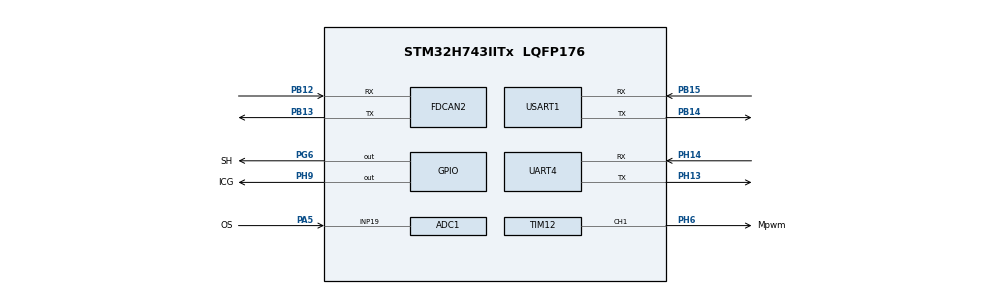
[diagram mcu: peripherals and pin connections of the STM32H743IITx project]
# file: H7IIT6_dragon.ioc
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ADC1.Channel-15\#ChannelRegularConversion=ADC_CHANNEL_19
ADC1.ClockPrescaler=ADC_CLOCK_ASYNC_DIV4
ADC1.ContinuousConvMode=ENABLE
ADC1.ConversionDataManagement=ADC_CONVERSIONDATA_DMA_CIRCULAR
ADC1.NbrOfConversionFlag=1
ADC1.OffsetNumber-15\#ChannelRegularConversion=ADC_OFFSET_NONE
ADC1.OffsetSignedSaturation-15\#ChannelRegularConversion=DISABLE
ADC1.Rank-15\#ChannelRegularConversion=1
ADC1.Resolution=ADC_RESOLUTION_12B
ADC1.SamplingTime-15\#ChannelRegularConversion=ADC_SAMPLETIME_1CYCLE_5
ADC1.master=1
CORTEX_M7.default_mode_Activation=1
Dma.ADC1.0.Direction=DMA_PERIPH_TO_MEMORY
Dma.ADC1.0.EventEnable=DISABLE
Dma.ADC1.0.FIFOMode=DMA_FIFOMODE_DISABLE
Dma.ADC1.0.Instance=DMA1_Stream0
Dma.ADC1.0.MemDataAlignment=DMA_MDATAALIGN_HALFWORD
Dma.ADC1.0.MemInc=DMA_MINC_ENABLE
Dma.ADC1.0.Mode=DMA_CIRCULAR
Dma.ADC1.0.PeriphDataAlignment=DMA_PDATAALIGN_HALFWORD
Dma.ADC1.0.PeriphInc=DMA_PINC_DISABLE
Dma.ADC1.0.Polarity=HAL_DMAMUX_REQ_GEN_RISING
Dma.ADC1.0.Priority=DMA_PRIORITY_LOW
Dma.ADC1.0.RequestNumber=1
Dma.ADC1.0.SignalID=NONE
Dma.ADC1.0.SyncEnable=DISABLE
Dma.ADC1.0.SyncPolarity=HAL_DMAMUX_SYNC_NO_EVENT
Dma.ADC1.0.SyncRequestNumber=1
Dma.ADC1.0.SyncSignalID=NONE
Dma.Request0=ADC1
Dma.Request1=UART4_TX
Dma.Request2=UART4_RX
Dma.UART4_RX.2.Direction=DMA_PERIPH_TO_MEMORY
Dma.UART4_RX.2.EventEnable=DISABLE
Dma.UART4_RX.2.FIFOMode=DMA_FIFOMODE_DISABLE
Dma.UART4_RX.2.Instance=DMA1_Stream2
Dma.UART4_RX.2.MemDataAlignment=DMA_MDATAALIGN_BYTE
Dma.UART4_RX.2.MemInc=DMA_MINC_ENABLE
Dma.UART4_RX.2.Mode=DMA_NORMAL
Dma.UART4_RX.2.PeriphDataAlignment=DMA_PDATAALIGN_BYTE
Dma.UART4_RX.2.PeriphInc=DMA_PINC_DISABLE
Dma.UART4_RX.2.Polarity=HAL_DMAMUX_REQ_GEN_RISING
Dma.UART4_RX.2.Priority=DMA_PRIORITY_LOW
Dma.UART4_RX.2.RequestNumber=1
Dma.UART4_RX.2.SignalID=NONE
Dma.UART4_RX.2.SyncEnable=DISABLE
Dma.UART4_RX.2.SyncPolarity=HAL_DMAMUX_SYNC_NO_EVENT
Dma.UART4_RX.2.SyncRequestNumber=1
Dma.UART4_RX.2.SyncSignalID=NONE
Dma.UART4_TX.1.Direction=DMA_MEMORY_TO_PERIPH
Dma.UART4_TX.1.EventEnable=DISABLE
Dma.UART4_TX.1.FIFOMode=DMA_FIFOMODE_DISABLE
Dma.UART4_TX.1.Instance=DMA1_Stream1
Dma.UART4_TX.1.MemDataAlignment=DMA_MDATAALIGN_BYTE
Dma.UART4_TX.1.MemInc=DMA_MINC_ENABLE
Dma.UART4_TX.1.Mode=DMA_NORMAL
Dma.UART4_TX.1.PeriphDataAlignment=DMA_PDATAALIGN_BYTE
Dma.UART4_TX.1.PeriphInc=DMA_PINC_DISABLE
Dma.UART4_TX.1.Polarity=HAL_DMAMUX_REQ_GEN_RISING
Dma.UART4_TX.1.Priority=DMA_PRIORITY_LOW
Dma.UART4_TX.1.RequestNumber=1
Dma.UART4_TX.1.SignalID=NONE
Dma.UART4_TX.1.SyncEnable=DISABLE
Dma.UART4_TX.1.SyncPolarity=HAL_DMAMUX_SYNC_NO_EVENT
Dma.UART4_TX.1.SyncRequestNumber=1
Dma.UART4_TX.1.SyncSignalID=NONE
FDCAN2.CalculateBaudRateNominal=1499999
FDCAN2.CalculateTimeBitNominal=666
FDCAN2.CalculateTimeQuantumNominal=133.33333333333334
Mcu.Family=STM32H7
Mcu.Name=STM32H743IITx
Mcu.Package=LQFP176
NVIC.DMA1_Stream0_IRQn=true\:0\:0\:false\:false\:true\:false\:true\:true
NVIC.DMA1_Stream1_IRQn=true\:0\:0\:false\:false\:true\:false\:true\:true
NVIC.DMA1_Stream2_IRQn=true\:0\:0\:false\:false\:true\:false\:true\:true
NVIC.PriorityGroup=NVIC_PRIORITYGROUP_4
NVIC.TIM2_IRQn=true\:0\:0\:false\:false\:true\:true\:true\:true
NVIC.UART4_IRQn=true\:0\:0\:false\:false\:true\:true\:true\:true
PA13\ (JTMS/SWDIO).Mode=Serial_Wire
PA13\ (JTMS/SWDIO).Signal=DEBUG_JTMS-SWDIO
PA14\ (JTCK/SWCLK).Mode=Serial_Wire
PA14\ (JTCK/SWCLK).Signal=DEBUG_JTCK-SWCLK
PA5.GPIO_Label=OS
PA5.Signal=ADCx_INP19
PB12.Mode=FDCAN_Activate
PB12.Signal=FDCAN2_RX
PB13.Mode=FDCAN_Activate
PB13.Signal=FDCAN2_TX
PB14.Mode=Asynchronous
PB14.Signal=USART1_TX
PB15.Mode=Asynchronous
PB15.Signal=USART1_RX
PG6.GPIO_Label=SH
PG6.Signal=GPIO_Output
PH13.GPIO_Speed=GPIO_SPEED_FREQ_VERY_HIGH
PH13.Mode=Asynchronous
PH13.Signal=UART4_TX
PH14.GPIO_Speed=GPIO_SPEED_FREQ_VERY_HIGH
PH14.Mode=Asynchronous
PH14.Signal=UART4_RX
PH6.GPIO_Label=Mpwm
PH6.Signal=S_TIM12_CH1
PH9.GPIO_Label=ICG
PH9.GPIO_Speed=GPIO_SPEED_FREQ_VERY_HIGH
PH9.PinState=GPIO_PIN_SET
PH9.Signal=GPIO_Output
ProjectManager.HeapSize=0x200
ProjectManager.StackSize=0x400
ProjectManager.TargetToolchain=MDK-ARM V5.32
RCC.ADCCLockSelection=RCC_ADCCLKSOURCE_CLKP
RCC.ADCFreq_Value=64000000
RCC.APB1Freq_Value=120000000
RCC.APB2Freq_Value=120000000
RCC.APB3Freq_Value=120000000
RCC.APB4Freq_Value=120000000
RCC.CortexFreq_Value=480000000
RCC.D1PPRE=RCC_APB3_DIV2
RCC.D2PPRE1=RCC_APB1_DIV2
RCC.D2PPRE2=RCC_APB2_DIV2
RCC.D3PPRE=RCC_APB4_DIV2
RCC.DIVM1=4
RCC.DIVN1=60
RCC.DIVQ1=8
RCC.HCLKFreq_Value=240000000
RCC.HPRE=RCC_HCLK_DIV2
RCC.SYSCLKFreq_VALUE=480000000
RCC.SYSCLKSource=RCC_SYSCLKSOURCE_PLLCLK
RCC.USBFreq_Value=120000000
SH.ADCx_INP19.0=ADC1_INP19,IN19-Single-Ended
SH.S_TIM12_CH1.0=TIM12_CH1,PWM Generation1 CH1
TIM12.AutoReloadPreload=TIM_AUTORELOAD_PRELOAD_ENABLE
TIM12.Channel-PWM\ Generation1\ CH1=TIM_CHANNEL_1
TIM12.OCFastMode_PWM-PWM\ Generation1\ CH1=TIM_OCFAST_ENABLE
TIM12.Period=120-1
TIM12.Pulse-PWM\ Generation1\ CH1=60
TIM2.AutoReloadPreload=TIM_AUTORELOAD_PRELOAD_ENABLE
TIM2.Period=100-1
TIM2.Prescaler=24000-1
TIM4.AutoReloadPreload=TIM_AUTORELOAD_PRELOAD_ENABLE
TIM4.Period=1000-1
TIM4.Prescaler=120-1
USART1.VirtualMode-Asynchronous=VM_ASYNC
VP_MEMORYMAP_VS_MEMORYMAP.Mode=CurAppReg
VP_TIM12_VS_ClockSourceINT.Mode=Internal
VP_TIM2_VS_ClockSourceINT.Mode=Internal
VP_TIM4_VS_ClockSourceINT.Mode=Internal
board=custom

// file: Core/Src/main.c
/* USER CODE BEGIN Header */
/**
  ******************************************************************************
  * @file           : main.c
  * @brief          : Main program body
  ******************************************************************************
  * @attention
  *
  * Copyright (c) 2024 STMicroelectronics.
  * All rights reserved.
  *
  * This software is licensed under terms that can be found in the LICENSE file
  * in the root directory of this software component.
  * If no LICENSE file comes with this software, it is provided AS-IS.
  *
  ******************************************************************************
  */
/* USER CODE END Header */
#include "main.h"
#include "adc.h"
#include "dma.h"
#include "fdcan.h"
#include "memorymap.h"
#include "tim.h"
#include "usart.h"
#include "gpio.h"

void SystemClock_Config(void);
void PeriphCommonClock_Config(void);
static void MPU_Config(void);

int main(void)
{

  /* MPU Configuration--------------------------------------------------------*/
  MPU_Config();

  /* MCU Configuration--------------------------------------------------------*/

  /* Reset of all peripherals, Initializes the Flash interface and the Systick. */
  HAL_Init();

  /* Configure the system clock */
  SystemClock_Config();

  /* Configure the peripherals common clocks */
  PeriphCommonClock_Config();

  /* Initialize all configured peripherals */
  MX_GPIO_Init();
  MX_DMA_Init();
  MX_FDCAN2_Init();
  MX_USART1_UART_Init();
  MX_ADC1_Init();
  MX_TIM2_Init();
  MX_TIM12_Init();
  MX_UART4_Init();
  MX_TIM4_Init();
  /* USER CODE BEGIN 2 */
    HAL_TIM_PWM_Start(&htim12,TIM_CHANNEL_1);
    __HAL_TIM_SetCompare(&htim12,TIM_CHANNEL_1,60);
    HAL_TIM_Base_Start_IT(&htim2);
    HAL_ADC_Start_DMA(&hadc1, (uint8_t*)adc_buffer,ADC_BUFFER_SIZE);
  /* USER CODE END 2 */

  /* Infinite loop */
    while (1)
    {

    /* USER CODE BEGIN 3 */

				// 	HAL_GPIO_WritePin(ICG_GPIO_Port, ICG_Pin, GPIO_PIN_SET);//清除积分
        //     HAL_Delay(1); // 控制采样间隔
        // HAL_GPIO_WritePin(ICG_GPIO_Port, ICG_Pin, GPIO_PIN_RESET);//开始积分
        // // 采样 SH 信号
        // HAL_ADC_Start_DMA(&hadc1, (uint8_t*)adc_buffer,ADC_BUFFER_SIZE);
        // for(int i=0; i<ADC_BUFFER_SIZE; i++)
        // {
        //     Trigger_Shift_Pulse();
        // }
        // HAL_Delay(1); // 保持高电平一段时间
task1();
// printf("223");
    }

  /* USER CODE END 3 */
}

void SystemClock_Config(void)
{
  RCC_OscInitTypeDef RCC_OscInitStruct = {0};
  RCC_ClkInitTypeDef RCC_ClkInitStruct = {0};

  /** Supply configuration update enable
  */
  HAL_PWREx_ConfigSupply(PWR_LDO_SUPPLY);

  /** Configure the main internal regulator output voltage
  */
  __HAL_PWR_VOLTAGESCALING_CONFIG(PWR_REGULATOR_VOLTAGE_SCALE1);

  while(!__HAL_PWR_GET_FLAG(PWR_FLAG_VOSRDY)) {}

  __HAL_RCC_SYSCFG_CLK_ENABLE();
  __HAL_PWR_VOLTAGESCALING_CONFIG(PWR_REGULATOR_VOLTAGE_SCALE0);

  while(!__HAL_PWR_GET_FLAG(PWR_FLAG_VOSRDY)) {}

  /** Initializes the RCC Oscillators according to the specified parameters
  * in the RCC_OscInitTypeDef structure.
  */
  RCC_OscInitStruct.OscillatorType = RCC_OSCILLATORTYPE_HSI;
  RCC_OscInitStruct.HSIState = RCC_HSI_DIV1;
  RCC_OscInitStruct.HSICalibrationValue = RCC_HSICALIBRATION_DEFAULT;
  RCC_OscInitStruct.PLL.PLLState = RCC_PLL_ON;
  RCC_OscInitStruct.PLL.PLLSource = RCC_PLLSOURCE_HSI;
  RCC_OscInitStruct.PLL.PLLM = 4;
  RCC_OscInitStruct.PLL.PLLN = 60;
  RCC_OscInitStruct.PLL.PLLP = 2;
  RCC_OscInitStruct.PLL.PLLQ = 8;
  RCC_OscInitStruct.PLL.PLLR = 2;
  RCC_OscInitStruct.PLL.PLLRGE = RCC_PLL1VCIRANGE_3;
  RCC_OscInitStruct.PLL.PLLVCOSEL = RCC_PLL1VCOWIDE;
  RCC_OscInitStruct.PLL.PLLFRACN = 0;
  if (HAL_RCC_OscConfig(&RCC_OscInitStruct) != HAL_OK)
  {
    Error_Handler();
  }

  /** Initializes the CPU, AHB and APB buses clocks
  */
  RCC_ClkInitStruct.ClockType = RCC_CLOCKTYPE_HCLK|RCC_CLOCKTYPE_SYSCLK
                              |RCC_CLOCKTYPE_PCLK1|RCC_CLOCKTYPE_PCLK2
                              |RCC_CLOCKTYPE_D3PCLK1|RCC_CLOCKTYPE_D1PCLK1;
  RCC_ClkInitStruct.SYSCLKSource = RCC_SYSCLKSOURCE_PLLCLK;
  RCC_ClkInitStruct.SYSCLKDivider = RCC_SYSCLK_DIV1;
  RCC_ClkInitStruct.AHBCLKDivider = RCC_HCLK_DIV2;
  RCC_ClkInitStruct.APB3CLKDivider = RCC_APB3_DIV2;
  RCC_ClkInitStruct.APB1CLKDivider = RCC_APB1_DIV2;
  RCC_ClkInitStruct.APB2CLKDivider = RCC_APB2_DIV2;
  RCC_ClkInitStruct.APB4CLKDivider = RCC_APB4_DIV2;

  if (HAL_RCC_ClockConfig(&RCC_ClkInitStruct, FLASH_LATENCY_4) != HAL_OK)
  {
    Error_Handler();
  }
}

void PeriphCommonClock_Config(void)
{
  RCC_PeriphCLKInitTypeDef PeriphClkInitStruct = {0};

  /** Initializes the peripherals clock
  */
  PeriphClkInitStruct.PeriphClockSelection = RCC_PERIPHCLK_CKPER;
  PeriphClkInitStruct.CkperClockSelection = RCC_CLKPSOURCE_HSI;
  if (HAL_RCCEx_PeriphCLKConfig(&PeriphClkInitStruct) != HAL_OK)
  {
    Error_Handler();
  }
}

 /* MPU Configuration */

void MPU_Config(void)
{
  MPU_Region_InitTypeDef MPU_InitStruct = {0};

  /* Disables the MPU */
  HAL_MPU_Disable();

  /** Initializes and configures the Region and the memory to be protected
  */
  MPU_InitStruct.Enable = MPU_REGION_ENABLE;
  MPU_InitStruct.Number = MPU_REGION_NUMBER0;
  MPU_InitStruct.BaseAddress = 0x0;
  MPU_InitStruct.Size = MPU_REGION_SIZE_4GB;
  MPU_InitStruct.SubRegionDisable = 0x87;
  MPU_InitStruct.TypeExtField = MPU_TEX_LEVEL0;
  MPU_InitStruct.AccessPermission = MPU_REGION_NO_ACCESS;
  MPU_InitStruct.DisableExec = MPU_INSTRUCTION_ACCESS_DISABLE;
  MPU_InitStruct.IsShareable = MPU_ACCESS_SHAREABLE;
  MPU_InitStruct.IsCacheable = MPU_ACCESS_NOT_CACHEABLE;
  MPU_InitStruct.IsBufferable = MPU_ACCESS_NOT_BUFFERABLE;

  HAL_MPU_ConfigRegion(&MPU_InitStruct);
  /* Enables the MPU */
  HAL_MPU_Enable(MPU_PRIVILEGED_DEFAULT);

}

void Error_Handler(void)
{
    __disable_irq();
    while (1)
    {
    }
}
